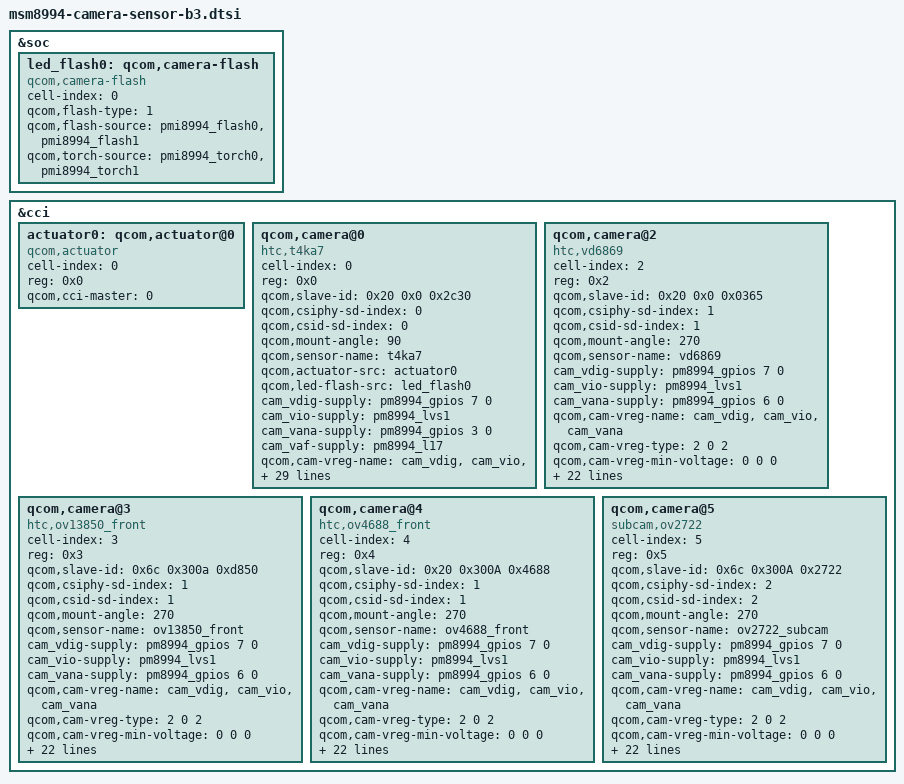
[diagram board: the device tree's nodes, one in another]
/*
 * Copyright (c) 2014, The Linux Foundation. All rights reserved.
 *
 * This program is free software; you can redistribute it and/or modify
 * it under the terms of the GNU General Public License version 2 and
 * only version 2 as published by the Free Software Foundation.
 *
 * This program is distributed in the hope that it will be useful,
 * but WITHOUT ANY WARRANTY; without even the implied warranty of
 * MERCHANTABILITY or FITNESS FOR A PARTICULAR PURPOSE.  See the
 * GNU General Public License for more details.
 */

&soc {
	led_flash0: qcom,camera-flash {
		cell-index = <0>;
		compatible = "qcom,camera-flash";
		qcom,flash-type = <1>;
		qcom,flash-source = <&pmi8994_flash0 &pmi8994_flash1>;
		qcom,torch-source = <&pmi8994_torch0 &pmi8994_torch1>;
	};
};
&cci {
	actuator0: qcom,actuator@0 {
		cell-index = <0>;
		reg = <0x0>;
		compatible = "qcom,actuator";
		qcom,cci-master = <0>;
	};

	qcom,camera@0 {
		cell-index = <0>;
		compatible = "htc,t4ka7";
		reg = <0x0>;
		qcom,slave-id = <0x20 0x0 0x2c30>;
		qcom,csiphy-sd-index = <0>;
		qcom,csid-sd-index = <0>;
		qcom,mount-angle = <90>;
		qcom,sensor-name = "t4ka7";
		qcom,actuator-src = <&actuator0>;
		qcom,led-flash-src = <&led_flash0>;
		cam_vdig-supply = <&pm8994_gpios 7 0>;
		cam_vio-supply = <&pm8994_lvs1>;
		cam_vana-supply = <&pm8994_gpios 3 0>;
		cam_vaf-supply = <&pm8994_l17>;
		qcom,cam-vreg-name = "cam_vdig", "cam_vio", "cam_vana", "cam_vaf";
		qcom,cam-vreg-type = <2 0 2 0>;
		qcom,cam-vreg-min-voltage = <0 0 0 2800000>;
		qcom,cam-vreg-max-voltage = <0 0 0 2800000>;
		qcom,cam-vreg-op-mode = <0 0 0 0>;
		qcom,cam-vreg-gpios-index = <4 99 3 99>;
		qcom,gpio-no-mux = <0>;
		pinctrl-names = "cam_default", "cam_suspend";
		pinctrl-0 = <&cam_sensor_mclk0_active &cam_sensor_rear_active>;
		pinctrl-1 = <&cam_sensor_mclk0_suspend &cam_sensor_rear_suspend>;
		gpios = <&msm_gpio 13 0>,
			<&msm_gpio 103 0>,
			<&msm_gpio 104 0>,
			<&pm8994_gpios 3 0>,
			<&pm8994_gpios 7 0>,
			<&pm8994_gpios 17 0>;
		qcom,gpio-reset = <1>;
		qcom,gpio-standby = <2>;
		qcom,gpio-vdig = <5>;
		qcom,gpio-req-tbl-num = <0 1 2 3 4 5>;
		qcom,gpio-req-tbl-flags = <1 0 0 0 0 0>;
		qcom,gpio-req-tbl-label = "CAM_MCLK0",
					  "CAM_RESET0",
					  "CAM_VCM_PD",
					  "CAM_A2V8_EN",
					  "CAM2_D1V2_EN",
					  "SENSOR_GPIO_VDIG";

		qcom,csi-lane-assign = <0x4320>;
		qcom,csi-lane-mask = <0x1F>;
		qcom,sensor-position = <0>;
		qcom,sensor-mode = <1>;
		qcom,cci-master = <0>;
		status = "ok";
		clocks = <&clock_mmss clk_mclk0_clk_src>,
				<&clock_mmss clk_camss_mclk0_clk>;
		clock-names = "cam_src_clk", "cam_clk";
	};

	/*qcom,camera@1 {
		cell-index = <1>;
		compatible = "htc,imx220";
		reg = <0x1>;
		qcom,slave-id = <0x20 0x0016 0x0220>;
		qcom,csiphy-sd-index = <0>;
		qcom,csid-sd-index = <0>;
		qcom,mount-angle = <90>;
		qcom,sensor-name = "imx220";
		qcom,actuator-src = <&actuator0>;
		qcom,led-flash-src = <&led_flash0>;
		cam_vdig-supply = <&pm8994_gpios 7 0>;
		cam_vio-supply = <&pm8994_lvs1>;
		cam_vana-supply = <&pm8994_gpios 3 0>;
		cam_vaf-supply = <&pm8994_l17>;
		qcom,cam-vreg-name = "cam_vdig", "cam_vio", "cam_vana", "cam_vaf";
		qcom,cam-vreg-type = <2 0 2 0>;
		qcom,cam-vreg-min-voltage = <0 0 0 2800000>;
		qcom,cam-vreg-max-voltage = <0 0 0 2800000>;
		qcom,cam-vreg-op-mode = <0 0 0 0>;
		qcom,cam-vreg-gpios-index = <4 99 3 99>;
		qcom,gpio-no-mux = <0>;
		pinctrl-names = "cam_default", "cam_suspend";
		pinctrl-0 = <&cam_sensor_mclk0_active &cam_sensor_rear_active>;
		pinctrl-1 = <&cam_sensor_mclk0_suspend &cam_sensor_rear_suspend>;
		gpios = <&msm_gpio 13 0>,
			<&msm_gpio 103 0>,
			<&msm_gpio 104 0>,
			<&pm8994_gpios 3 0>,
			<&pm8994_gpios 7 0>;
		qcom,gpio-reset = <1>;
		qcom,gpio-standby = <2>;
		qcom,gpio-req-tbl-num = <0 1 2 3 4>;
		qcom,gpio-req-tbl-flags = <1 0 0 0 0>;
		qcom,gpio-req-tbl-label = "CAM_MCLK0",
					  "CAM_RESET0",
					  "CAM_VCM_PD",
					  "CAM_A2V8_EN",
					  "CAM2_D1V2_EN";

		qcom,csi-lane-assign = <0x4320>;
		qcom,csi-lane-mask = <0x1F>;
		qcom,sensor-position = <0>;
		qcom,sensor-mode = <1>;
		qcom,cci-master = <0>;
		status = "ok";
		clocks = <&clock_mmss clk_mclk0_clk_src>,
				<&clock_mmss clk_camss_mclk0_clk>;
		clock-names = "cam_src_clk", "cam_clk";
	};
*/
	qcom,camera@2 {
		cell-index = <2>;
		compatible = "htc,vd6869";
		reg = <0x2>;
		qcom,slave-id = <0x20 0x0 0x0365>;
		qcom,csiphy-sd-index = <1>;
		qcom,csid-sd-index = <1>;
		qcom,mount-angle = <270>;
		qcom,sensor-name = "vd6869";
		cam_vdig-supply = <&pm8994_gpios 7 0>;
		cam_vio-supply = <&pm8994_lvs1>;
		cam_vana-supply = <&pm8994_gpios 6 0>;
		qcom,cam-vreg-name = "cam_vdig", "cam_vio", "cam_vana";
		qcom,cam-vreg-type = <2 0 2>;
		qcom,cam-vreg-min-voltage = <0 0 0>;
		qcom,cam-vreg-max-voltage = <0 0 0>;
		qcom,cam-vreg-op-mode = <0 0 0>;
		qcom,cam-vreg-gpios-index = <3 99 2>;
		qcom,gpio-no-mux = <0>;
		pinctrl-names = "cam_default", "cam_suspend";
		pinctrl-0 = <&cam_sensor_mclk1_active &cam_sensor_front_active>;
		pinctrl-1 = <&cam_sensor_mclk1_suspend &cam_sensor_front_suspend>;
		gpios = <&msm_gpio 14 0>,
			<&msm_gpio 105 0>,
			<&pm8994_gpios 6 0>,
			<&pm8994_gpios 7 0>;
		qcom,gpio-reset = <1>;
		qcom,gpio-req-tbl-num = <0 1 2 3>;
		qcom,gpio-req-tbl-flags = <1 0 0 0>;
		qcom,gpio-req-tbl-label = "CAM_MCLK1",
					  "CAM_RESET1",
					  "CAM2_A2V9_EN",
					  "CAM2_D1V2_EN";

		qcom,csi-lane-assign = <0x4320>;
		qcom,csi-lane-mask = <0x1F>;
		qcom,sensor-position = <1>;
		qcom,sensor-mode = <1>;
		qcom,cci-master = <1>;
		status = "ok";
		clocks = <&clock_mmss clk_mclk1_clk_src>,
				<&clock_mmss clk_camss_mclk1_clk>;
		clock-names = "cam_src_clk", "cam_clk";
	};

	qcom,camera@3 {
		cell-index = <3>;
		compatible = "htc,ov13850_front";
		reg = <0x3>;
		qcom,slave-id = <0x6c 0x300a 0xd850>;
		qcom,csiphy-sd-index = <1>;
		qcom,csid-sd-index = <1>;
		qcom,mount-angle = <270>;
		qcom,sensor-name = "ov13850_front";
		cam_vdig-supply = <&pm8994_gpios 7 0>;
		cam_vio-supply = <&pm8994_lvs1>;
		cam_vana-supply = <&pm8994_gpios 6 0>;
		qcom,cam-vreg-name = "cam_vdig", "cam_vio", "cam_vana";
		qcom,cam-vreg-type = <2 0 2>;
		qcom,cam-vreg-min-voltage = <0 0 0>;
		qcom,cam-vreg-max-voltage = <0 0 0>;
		qcom,cam-vreg-op-mode = <0 0 0>;
		qcom,cam-vreg-gpios-index = <3 99 2>;
		qcom,gpio-no-mux = <0>;
		pinctrl-names = "cam_default", "cam_suspend";
		pinctrl-0 = <&cam_sensor_mclk1_active &cam_sensor_front_active>;
		pinctrl-1 = <&cam_sensor_mclk1_suspend &cam_sensor_front_suspend>;
		gpios = <&msm_gpio 14 0>,
			<&msm_gpio 105 0>,
			<&pm8994_gpios 6 0>,
			<&pm8994_gpios 7 0>;
		qcom,gpio-reset = <1>;
		qcom,gpio-req-tbl-num = <0 1 2 3>;
		qcom,gpio-req-tbl-flags = <1 0 0 0>;
		qcom,gpio-req-tbl-label = "CAM_MCLK1",
					  "CAM_RESET1",
					  "CAM2_A2V9_EN",
					  "CAM2_D1V2_EN";

		qcom,csi-lane-assign = <0x4320>;
		qcom,csi-lane-mask = <0x1F>;
		qcom,sensor-position = <1>;
		qcom,sensor-mode = <1>;
		qcom,cci-master = <1>;
		status = "ok";
		clocks = <&clock_mmss clk_mclk1_clk_src>,
				<&clock_mmss clk_camss_mclk1_clk>;
		clock-names = "cam_src_clk", "cam_clk";
	};

	qcom,camera@4 {
		cell-index = <4>;
		compatible = "htc,ov4688_front";
		reg = <0x4>;
		qcom,slave-id = <0x20 0x300A 0x4688>;
		qcom,csiphy-sd-index = <1>;
		qcom,csid-sd-index = <1>;
		qcom,mount-angle = <270>;
		qcom,sensor-name = "ov4688_front";
		cam_vdig-supply = <&pm8994_gpios 7 0>;
		cam_vio-supply = <&pm8994_lvs1>;
		cam_vana-supply = <&pm8994_gpios 6 0>;
		qcom,cam-vreg-name = "cam_vdig", "cam_vio", "cam_vana";
		qcom,cam-vreg-type = <2 0 2>;
		qcom,cam-vreg-min-voltage = <0 0 0>;
		qcom,cam-vreg-max-voltage = <0 0 0>;
		qcom,cam-vreg-op-mode = <0 0 0>;
		qcom,cam-vreg-gpios-index = <3 99 2>;
		qcom,gpio-no-mux = <0>;
		pinctrl-names = "cam_default", "cam_suspend";
		pinctrl-0 = <&cam_sensor_mclk1_active &cam_sensor_front_active>;
		pinctrl-1 = <&cam_sensor_mclk1_suspend &cam_sensor_front_suspend>;
		gpios = <&msm_gpio 14 0>,
			<&msm_gpio 105 0>,
			<&pm8994_gpios 6 0>,
			<&pm8994_gpios 7 0>;
		qcom,gpio-reset = <1>;
		qcom,gpio-req-tbl-num = <0 1 2 3>;
		qcom,gpio-req-tbl-flags = <1 0 0 0>;
		qcom,gpio-req-tbl-label = "CAM_MCLK1",
					  "CAM_RESET1",
					  "CAM2_A2V9_EN",
					  "CAM2_D1V2_EN";

		qcom,csi-lane-assign = <0x4320>;
		qcom,csi-lane-mask = <0x1F>;
		qcom,sensor-position = <1>;
		qcom,sensor-mode = <1>;
		qcom,cci-master = <1>;
		status = "ok";
		clocks = <&clock_mmss clk_mclk1_clk_src>,
				<&clock_mmss clk_camss_mclk1_clk>;
		clock-names = "cam_src_clk", "cam_clk";
	};

	qcom,camera@5 {
		cell-index = <5>;
		compatible = "subcam,ov2722";
		reg = <0x5>;
		qcom,slave-id = <0x6c 0x300A 0x2722>;
		qcom,csiphy-sd-index = <2>;
		qcom,csid-sd-index = <2>;
		qcom,mount-angle = <270>;
		qcom,sensor-name = "ov2722_subcam";
		cam_vdig-supply = <&pm8994_gpios 7 0>;
		cam_vio-supply = <&pm8994_lvs1>;
		cam_vana-supply = <&pm8994_gpios 6 0>;
		qcom,cam-vreg-name = "cam_vdig", "cam_vio", "cam_vana";
		qcom,cam-vreg-type = <2 0 2>;
		qcom,cam-vreg-min-voltage = <0 0 0>;
		qcom,cam-vreg-max-voltage = <0 0 0>;
		qcom,cam-vreg-op-mode = <0 0 0>;
		qcom,cam-vreg-gpios-index = <3 99 2>;
		qcom,gpio-no-mux = <0>;
		pinctrl-names = "cam_default", "cam_suspend";
		pinctrl-0 = <&cam_sensor_mclk2_active &cam_sensor_rear2_active>;
		pinctrl-1 = <&cam_sensor_mclk2_suspend &cam_sensor_rear2_suspend>;
		gpios =  <&msm_gpio 15 0>,
			<&msm_gpio 109 0>,
			<&pm8994_gpios 6 0>,
			<&pm8994_gpios 7 0>;
		qcom,gpio-reset = <1>;
		qcom,gpio-req-tbl-num = <0 1 2 3>;
		qcom,gpio-req-tbl-flags = <1 0 0 0>;
		qcom,gpio-req-tbl-label = "CAM_MCLK2",
					  "CAM_RESET2",
					  "CAM2_A2V9_EN",
					  "CAM2_D1V2_EN";

		qcom,csi-lane-assign = <0x4320>;
		qcom,csi-lane-mask = <0x3>;
		qcom,sensor-position = <2>; //subcam:2, front:1
		qcom,sensor-mode = <1>;
		qcom,cci-master = <1>;
		status = "ok";
		clocks = <&clock_mmss clk_mclk2_clk_src>,
				<&clock_mmss clk_camss_mclk2_clk>;
		clock-names = "cam_src_clk", "cam_clk";
	};
};

